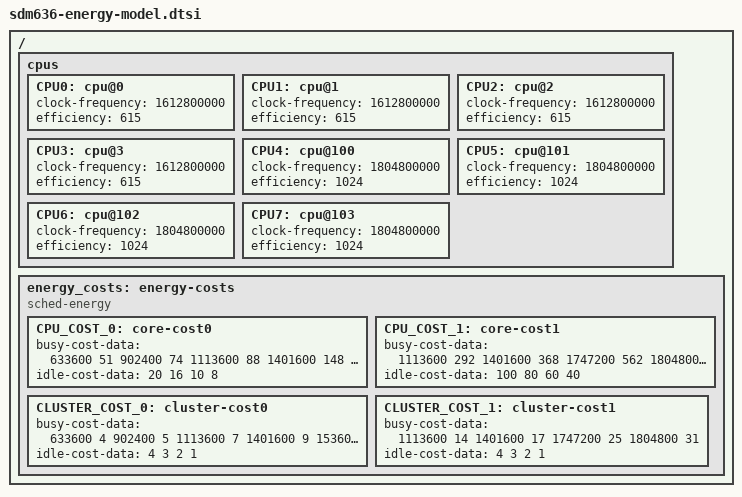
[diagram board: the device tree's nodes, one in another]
/*
 * This program is free software; you can redistribute it and/or modify
 * it under the terms of the GNU General Public License version 2 and
 * only version 2 as published by the Free Software Foundation.
 *
 * This program is distributed in the hope that it will be useful,
 * but WITHOUT ANY WARRANTY; without even the implied warranty of
 * MERCHANTABILITY or FITNESS FOR A PARTICULAR PURPOSE.  See the
 * GNU General Public License for more details.
 */
/ {
	cpus {
		CPU0: cpu@0 {
			clock-frequency = <1612800000>;
			efficiency = <615>;
			#cooling-cells = <2>;
			};
			
		CPU1: cpu@1 {
			clock-frequency = <1612800000>;
			efficiency = <615>;
			#cooling-cells = <2>;
			};
				
		CPU2: cpu@2 {
			clock-frequency = <1612800000>;
			efficiency = <615>;
			#cooling-cells = <2>;
			};
			
		CPU3: cpu@3 {	
			clock-frequency = <1612800000>;
			efficiency = <615>;
			#cooling-cells = <2>;
			};
						
		CPU4: cpu@100 {
			clock-frequency = <1804800000>;
			efficiency = <1024>;
			#cooling-cells = <2>;
			};
			
		CPU5: cpu@101 {
			clock-frequency = <1804800000>;
			efficiency = <1024>;
			#cooling-cells = <2>;
			};
			
		CPU6: cpu@102 {
			clock-frequency = <1804800000>;
			efficiency = <1024>;
			#cooling-cells = <2>;
			};
			
		CPU7: cpu@103 {
			clock-frequency = <1804800000>;
			efficiency = <1024>;
			#cooling-cells = <2>;
			};
	};

	energy_costs: energy-costs {
		compatible = "sched-energy";

		CPU_COST_0: core-cost0 {
			busy-cost-data = <
				633600	51
				902400	74
				1113600	88
				1401600	148
				1536000	162
				1612800	182
			>;
			idle-cost-data = <
				20 16 10 8
			>;
		};

		CPU_COST_1: core-cost1 {
			busy-cost-data = <
				1113600	292
				1401600	368
				1747200	562
				1804800	559
			>;
			idle-cost-data = <
				100 80 60 40
			>;
		};

		CLUSTER_COST_0: cluster-cost0 {
			busy-cost-data = <
				633600	4
				902400	5
				1113600	7
				1401600	9
				1536000	9
				1612800	11
			>;
			idle-cost-data = <
				4 3 2 1
			>;
		};

		CLUSTER_COST_1: cluster-cost1 {
			busy-cost-data = <
				1113600	14
				1401600	17
				1747200	25
				1804800	31
			>;
			idle-cost-data = <
				4 3 2 1
			>;
		};
	};		
};									
